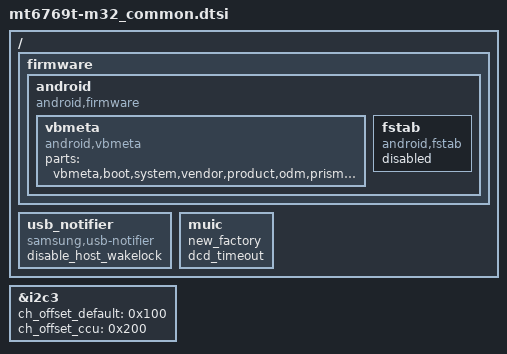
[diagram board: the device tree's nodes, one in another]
/* Generated by Samsung for MTK vendor board
 * If these files should be changed, then please make a sync with MTK
*/


#include "display_lcd_m32_common.dtsi"

/* Add Samsung configuration over here */
/ {
	fragment@model {
		target-path = "/";
		__overlay__ {
			firmware {
				android {
					compatible = "android,firmware";
					vbmeta {
						compatible = "android,vbmeta";
						parts = "vbmeta,boot,system,vendor,product,odm,prism,optics,vbmeta_system,recovery,lk,tee1";
					};
					fstab {
						compatible = "android,fstab";
						status = "disabled";
					};
				};
			};
			usb_notifier {
				compatible = "samsung,usb-notifier";
				disable_host_wakelock;
			};
			muic {
				new_factory;
				dcd_timeout;
			};
		};
	};
};

&i2c3 {
	ch_offset_default = <0x100>;
	ch_offset_ccu = <0x200>;
};
